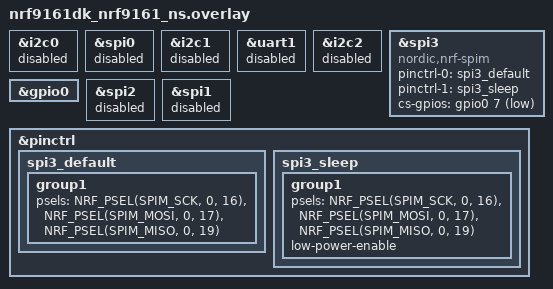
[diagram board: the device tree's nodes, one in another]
&i2c0 {	status = "disabled";};
&spi0 {	status = "disabled";};
&i2c1 {	status = "disabled";};
&uart1 { status = "disabled";};
&i2c2 { status = "disabled";};

&spi3 {
    status = "okay";
    compatible = "nordic,nrf-spim";
    pinctrl-0 = <&spi3_default>;
    pinctrl-1 = <&spi3_sleep>;
    pinctrl-names = "default", "sleep";
    cs-gpios = <&gpio0 7 GPIO_ACTIVE_LOW>;
};

&gpio0 {
    status = "okay";
};

&spi2 {
    status = "disabled";
//    compatible = "nordic,nrf-spim";
//    pinctrl-0 = <&spi2_default>;
//    pinctrl-1 = <&spi2_sleep>;
//    pinctrl-names = "default", "sleep";
//    cs-gpios = <&gpio0 7 GPIO_ACTIVE_LOW>;
};

&spi1 {
    status = "disabled";
//    compatible = "nordic,nrf-spim";
//    pinctrl-0 = <&spi1_default>;
//    pinctrl-1 = <&spi1_sleep>;
//    pinctrl-names = "default", "sleep";
};

&pinctrl {
/* 
    spi1_default: spi1_default {
        group1 {
            psels = <NRF_PSEL(SPIM_SCK, 0, 16)>,					 
                    <NRF_PSEL(SPIM_MOSI, 0, 17)>,
                    <NRF_PSEL(SPIM_MISO, 0, 19)>;
        };
    };
    spi1_sleep: spi1_sleep {
        group1 {
            psels = <NRF_PSEL(SPIM_SCK, 0, 16)>,
                    <NRF_PSEL(SPIM_MOSI, 0, 17)>,
                    <NRF_PSEL(SPIM_MISO, 0, 19)>;
            low-power-enable;
        };
    };
 */
/*  
    spi2_default: spi2_default {
        group1 {
            psels = <NRF_PSEL(SPIM_SCK, 0, 16)>,					 
                    <NRF_PSEL(SPIM_MOSI, 0, 17)>,
                    <NRF_PSEL(SPIM_MISO, 0, 19)>;
        };
    };
    spi2_sleep: spi2_sleep {
        group1 {
            psels = <NRF_PSEL(SPIM_SCK, 0, 16)>,
                    <NRF_PSEL(SPIM_MOSI, 0, 17)>,
                    <NRF_PSEL(SPIM_MISO, 0, 19)>;
            low-power-enable;
        };
    };
 */

    spi3_default: spi3_default {
        group1 {
            psels = <NRF_PSEL(SPIM_SCK, 0, 16)>,					 
                    <NRF_PSEL(SPIM_MOSI, 0, 17)>,
                    <NRF_PSEL(SPIM_MISO, 0, 19)>;
        };
    };
    spi3_sleep: spi3_sleep {
        group1 {
            psels = <NRF_PSEL(SPIM_SCK, 0, 16)>,
                    <NRF_PSEL(SPIM_MOSI, 0, 17)>,
                    <NRF_PSEL(SPIM_MISO, 0, 19)>;
            low-power-enable;
        };
    };

};
